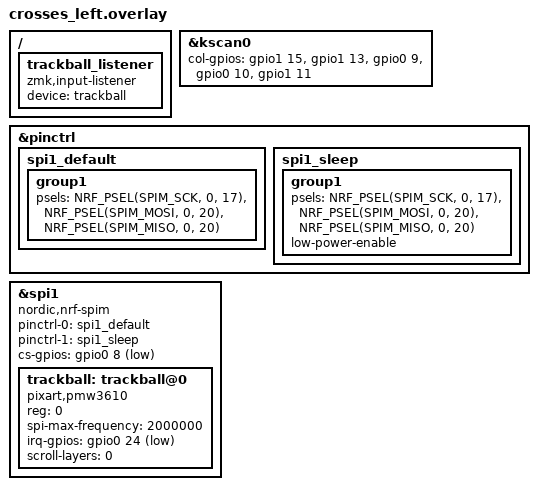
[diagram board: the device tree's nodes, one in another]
/*
 * Copyright (c) 2020 ZMK Contributors
 *
 * SPDX-License-Identifier: MIT
 */

#include "crosses.dtsi"

&kscan0 {
	col-gpios
		= <&gpio1 15 (GPIO_ACTIVE_HIGH | GPIO_PULL_DOWN)>
		, <&gpio1 13 (GPIO_ACTIVE_HIGH | GPIO_PULL_DOWN)>
		, <&gpio0 9 (GPIO_ACTIVE_HIGH | GPIO_PULL_DOWN)>
		, <&gpio0 10  (GPIO_ACTIVE_HIGH | GPIO_PULL_DOWN)>
		, <&gpio1 11 (GPIO_ACTIVE_HIGH | GPIO_PULL_DOWN)>

		;
};

// trackball bus
&pinctrl {
    spi1_default: spi1_default {
        group1 {
            psels = <NRF_PSEL(SPIM_SCK, 0, 17)>,
                <NRF_PSEL(SPIM_MOSI, 0, 20)>,
                <NRF_PSEL(SPIM_MISO, 0, 20)>;
        };
    };

    spi1_sleep: spi1_sleep {
        group1 {
            psels = <NRF_PSEL(SPIM_SCK, 0, 17)>,
                <NRF_PSEL(SPIM_MOSI, 0, 20)>,
                <NRF_PSEL(SPIM_MISO, 0, 20)>;
            low-power-enable;
        };
    };
};

&spi1 {
    status = "okay";
    compatible = "nordic,nrf-spim";
    pinctrl-0 = <&spi1_default>;
    pinctrl-1 = <&spi1_sleep>;
    pinctrl-names = "default", "sleep";
    cs-gpios = <&gpio0 8 GPIO_ACTIVE_LOW>;

    trackball: trackball@0 {
        status = "okay";
        compatible = "pixart,pmw3610";
        reg = <0>;
        spi-max-frequency = <2000000>;
        irq-gpios = <&gpio0 24 (GPIO_ACTIVE_LOW | GPIO_PULL_UP)>;
        scroll-layers = <0>;
        //snipe-layers = <2>;
        //automouse-layer = <3>;
    };
};





/ {
    trackball_listener {
        compatible = "zmk,input-listener";
        device = <&trackball>;
    };
};



